# DRM register map
Vendor: Texas Instruments
Peripheral module from a debugger description file (folder DRA74xP_75xP_76xP_77xP).
Registers are 32-bit, access per field, reset 0x0 unless marked. A register's access mark holds for its fields unless they carry their own. Offsets are as the file gives them; lines under a group give offsets from that group; [hi:lo] are bit positions; {n}, {i} and the like mark numbered series; 'fields as' and 'values as' point back to an identical list; <NAME> marks a mode.

## DRM
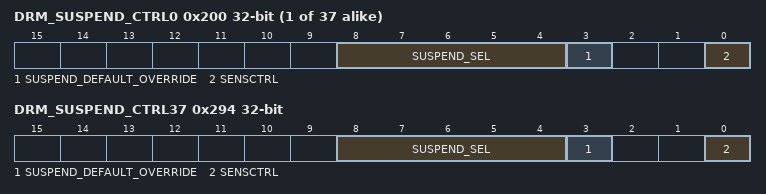
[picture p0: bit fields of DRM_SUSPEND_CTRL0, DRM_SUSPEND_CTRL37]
{0x200+4i} DRM_SUSPEND_CTRL{i} (i=0..36)
  [8:4] SUSPEND_SEL rw — Suspend signal selection. Selects which suspend signal affects the peripheral. Only valid when SUSPEND_DEFAULT_OVERRIDE=0 and SENSCTRL=1. When read, these bits reflect the default suspend signal. 0000b: CPU suspend signal. All other values are reserved.
  [3] SUSPEND_DEFAULT_OVERRIDE ro — Enable or disable the override value in SUSPEND_SEL. 0: SUSPEND_SEL field will select which suspend signal reaches the peripheral. 1: SUSPEND_SEL field ignored. Default suspend signal will reach the peripheral.
  [0] SENSCTRL rw — Sensitivity Control for suspend signals. When SUSPEND_DEFAULT_OVERRIDE=1, this bit is ignored and read as a 1. When SUSPEND_DEFAULT_OVERRIDE=0, 0: Suspend signal will not reach the peripheral. Peripheral will act as normal even during a debug halt. 1: Suspend signal will reach the peripheral. Peripheral will be suspended during debug halt.
0x294 DRM_SUSPEND_CTRL37 — susp
  fields as DRM_SUSPEND_CTRL0
